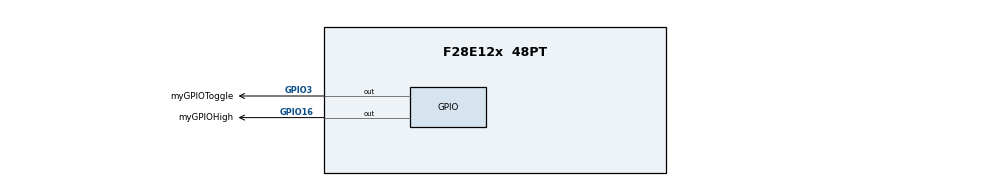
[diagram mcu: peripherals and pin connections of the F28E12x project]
/**
 * @cliArgs --board "/boards/LAUNCHXL_F28E12X" --device "F28E12x" --part "F28E12x_48PT" --package "48PT" --context "system" --product "C2000WARE@6.00.00.00"
 * @versions {"tool":"1.24.0+4109"}
 */

/**
 * Import the modules used in this configuration.
 */
const adc     = scripting.addModule("/driverlib/adc.js", {}, false);
const adc1    = adc.addInstance();
const analog  = scripting.addModule("/driverlib/analog.js", {}, false);
const analog1 = analog.addInstance();
const asysctl = scripting.addModule("/driverlib/asysctl.js");
const led     = scripting.addModule("/driverlib/board_components/led", {}, false);
const led1    = led.addInstance();
const gpio    = scripting.addModule("/driverlib/gpio.js", {}, false);
const gpio1   = gpio.addInstance();
const gpio2   = gpio.addInstance();
const mcpwm   = scripting.addModule("/driverlib/mcpwm.js");
const mcpwm1  = mcpwm.addInstance();

/**
 * Write custom configuration values to the imported modules.
 */
adc1.adcClockPrescaler       = "ADC_CLK_DIV_4_0";
adc1.enabledSOCs             = ["ADC_SOC_NUMBER0"];
adc1.soc0Trigger             = "ADC_TRIGGER_MCPWM1_SOCA";
adc1.registerInterrupts      = ["1"];
adc1.interruptPulseMode      = "ADC_PULSE_END_OF_CONV";
adc1.enabledInts             = ["ADC_INT_NUMBER1"];
adc1.enableInterrupt1        = true;
adc1.soc0SampleWindow        = 20;
adc1.$name                   = "myADCA";
adc1.adcInt1.enableInterrupt = true;

analog1.$name            = "myANALOGPinMux0";
adc1.analog              = analog1;
analog1.useCase          = "CUSTOM";
analog1.useInterfacePins = ["A0/CMP3_LITE_DACL/PGA1_INM2"];

asysctl.analogReference        = "INTERNAL";
asysctl.analogReferenceVoltage = "1P65";

led1.$name     = "myBoardLED0";
led1.$hardware = system.deviceData.board.components.LED5;

gpio1.$name                    = "myGPIOHigh";
gpio1.direction                = "GPIO_DIR_MODE_OUT";
gpio1.padConfig                = "PULLUP";
gpio1.writeInitialValue        = true;
gpio1.initialValue             = 1;
gpio1.gpioPin.$assign          = "GPIO16";
gpio1.gpioPin["GPIO#"].$assign = "boosterpack1.15";
scripting.suppress("Connected to hardware,@@@.+?@@@ is connected to SPIA BP on the LAUNCHXL-F28E12X\\. Consider selecting it in \'use hardware\' above\\. @@@.+?@@@", gpio1.gpioPin, "GPIO#");

gpio2.$name                    = "myGPIOToggle";
gpio2.direction                = "GPIO_DIR_MODE_OUT";
gpio2.padConfig                = "PULLUP";
gpio2.writeInitialValue        = true;
gpio2.initialValue             = 1;
gpio2.gpioPin.$assign          = "GPIO3";
gpio2.gpioPin["GPIO#"].$assign = "boosterpack1.37";

mcpwm.commentOutDefaultCode = true;

mcpwm1.$name                                               = "myMCPWM0";
mcpwm1.useCase                                             = "CUSTOM";
mcpwm1.mcpwmTimebase_period                                = 1999;
mcpwm1.mcpwmTimebase_counterMode                           = "MCPWM_COUNTER_MODE_UP";
mcpwm1.mcpwmEventTrigger_MCPWM_SOC_A_triggerEnable         = true;
mcpwm1.mcpwmEventTrigger_MCPWM_SOC_A_triggerSource         = "MCPWM_SOC_TBCTR_PERIOD";
mcpwm1.mcpwmEventTrigger_MCPWM_SOC_A_triggerEventPrescalar = "1";
